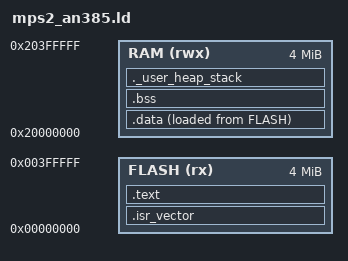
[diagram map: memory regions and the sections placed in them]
/* Linker script for the QEMU "mps2-an385" machine (Cortex-M3).
 *
 * Memory map matches QEMU's mps2-an385 model:
 *   - Code (ZBT SSRAM1):    0x00000000, 4M
 *   - SRAM (ZBT SSRAM2/3):  0x20000000, 4M
 */

MEMORY
{
    FLASH (rx) : ORIGIN = 0x00000000, LENGTH = 4M
    RAM (rwx)  : ORIGIN = 0x20000000, LENGTH = 4M
}

ENTRY(Reset_Handler)

_Min_Stack_Size = 0x1000;

SECTIONS
{
    .isr_vector :
    {
        . = ALIGN(4);
        KEEP(*(.isr_vector))
        . = ALIGN(4);
    } > FLASH

    .text :
    {
        . = ALIGN(4);
        *(.text*)
        *(.rodata*)
        . = ALIGN(4);
    } > FLASH

    _sidata = LOADADDR(.data);

    .data :
    {
        . = ALIGN(4);
        _sdata = .;
        *(.data*)
        . = ALIGN(4);
        _edata = .;
    } > RAM AT> FLASH

    .bss :
    {
        . = ALIGN(4);
        _sbss = .;
        *(.bss*)
        *(COMMON)
        . = ALIGN(4);
        _ebss = .;
    } > RAM

    ._user_heap_stack :
    {
        . = ALIGN(8);
        PROVIDE(end = .);
        PROVIDE(_end = .);
        . = . + _Min_Stack_Size;
        . = ALIGN(8);
    } > RAM

    _estack = ORIGIN(RAM) + LENGTH(RAM);

    /DISCARD/ :
    {
        *(.ARM.exidx*)
    }
}
